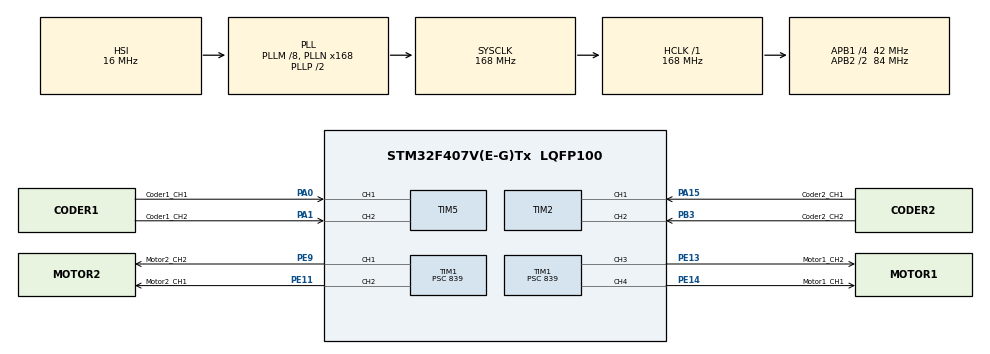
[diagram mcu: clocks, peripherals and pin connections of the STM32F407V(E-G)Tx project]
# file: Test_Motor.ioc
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Mcu.Family=STM32F4
Mcu.Name=STM32F407V(E-G)Tx
Mcu.Package=LQFP100
NVIC.PriorityGroup=NVIC_PRIORITYGROUP_4
NVIC.TIM6_DAC_IRQn=true\:0\:0\:false\:false\:true\:true\:true\:true
PA0-WKUP.GPIO_Label=Coder1_CH1
PA0-WKUP.Signal=S_TIM5_CH1
PA1.GPIO_Label=Coder1_CH2
PA1.Signal=S_TIM5_CH2
PA15.GPIO_Label=Coder2_CH1
PA15.Signal=S_TIM2_CH1_ETR
PB3.GPIO_Label=Coder2_CH2
PB3.Signal=S_TIM2_CH2
PC14-OSC32_IN.Mode=LSE-External-Oscillator
PC14-OSC32_IN.Signal=RCC_OSC32_IN
PC15-OSC32_OUT.Mode=LSE-External-Oscillator
PC15-OSC32_OUT.Signal=RCC_OSC32_OUT
PE11.GPIO_Label=Motor2_CH1
PE11.GPIO_Speed=GPIO_SPEED_FREQ_HIGH
PE11.Signal=S_TIM1_CH2
PE13.GPIO_Label=Motor1_CH2
PE13.GPIO_Speed=GPIO_SPEED_FREQ_HIGH
PE13.Signal=S_TIM1_CH3
PE14.GPIO_Label=Motor1_CH1
PE14.GPIO_Speed=GPIO_SPEED_FREQ_HIGH
PE14.Signal=S_TIM1_CH4
PE9.GPIO_Label=Motor2_CH2
PE9.GPIO_Speed=GPIO_SPEED_FREQ_HIGH
PE9.Signal=S_TIM1_CH1
PH0-OSC_IN.Mode=HSE-External-Oscillator
PH0-OSC_IN.Signal=RCC_OSC_IN
PH1-OSC_OUT.Mode=HSE-External-Oscillator
PH1-OSC_OUT.Signal=RCC_OSC_OUT
ProjectManager.HeapSize=0x200
ProjectManager.StackSize=0x400
ProjectManager.TargetToolchain=CMake
RCC.48MHZClocksFreq_Value=84000000
RCC.AHBFreq_Value=168000000
RCC.APB1CLKDivider=RCC_HCLK_DIV4
RCC.APB1Freq_Value=42000000
RCC.APB1TimFreq_Value=84000000
RCC.APB2CLKDivider=RCC_HCLK_DIV2
RCC.APB2Freq_Value=84000000
RCC.APB2TimFreq_Value=168000000
RCC.CortexFreq_Value=168000000
RCC.HCLKFreq_Value=168000000
RCC.HSE_VALUE=25000000
RCC.HSI_VALUE=16000000
RCC.PLLM=8
RCC.PLLN=168
RCC.SYSCLKFreq_VALUE=168000000
RCC.SYSCLKSource=RCC_SYSCLKSOURCE_PLLCLK
RCC.VCOOutputFreq_Value=336000000
SH.S_TIM1_CH1.0=TIM1_CH1,PWM Generation1 CH1
SH.S_TIM1_CH2.0=TIM1_CH2,PWM Generation2 CH2
SH.S_TIM1_CH3.0=TIM1_CH3,PWM Generation3 CH3
SH.S_TIM1_CH4.0=TIM1_CH4,PWM Generation4 CH4
SH.S_TIM2_CH1_ETR.0=TIM2_CH1,Encoder_Interface
SH.S_TIM2_CH2.0=TIM2_CH2,Encoder_Interface
SH.S_TIM5_CH1.0=TIM5_CH1,Encoder_Interface
SH.S_TIM5_CH2.0=TIM5_CH2,Encoder_Interface
TIM1.AutoReloadPreload=TIM_AUTORELOAD_PRELOAD_ENABLE
TIM1.Channel-PWM\ Generation1\ CH1=TIM_CHANNEL_1
TIM1.Channel-PWM\ Generation2\ CH2=TIM_CHANNEL_2
TIM1.Channel-PWM\ Generation3\ CH3=TIM_CHANNEL_3
TIM1.Channel-PWM\ Generation4\ CH4=TIM_CHANNEL_4
TIM1.Period=999
TIM1.Prescaler=839
TIM6.Period=10000
TIM6.Prescaler=83
VP_TIM1_VS_ClockSourceINT.Mode=Internal
VP_TIM6_VS_ClockSourceINT.Mode=Enable_Timer
board=custom

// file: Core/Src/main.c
/* USER CODE BEGIN Header */
/**
  ******************************************************************************
  * @file           : main.c
  * @brief          : Main program body
  ******************************************************************************
  * @attention
  *
  * Copyright (c) 2026 STMicroelectronics.
  * All rights reserved.
  *
  * This software is licensed under terms that can be found in the LICENSE file
  * in the root directory of this software component.
  * If no LICENSE file comes with this software, it is provided AS-IS.
  *
  ******************************************************************************
  */
/* USER CODE END Header */
#include "main.h"
#include "tim.h"
#include "gpio.h"

/* USER CODE BEGIN Includes */
#include "encoder_motor.h"
#include "motor_porting.h"
#include "pid.h"
#include <stdio.h>
/* USER CODE END Includes */

void SystemClock_Config(void);

int main(void)
{

  /* MCU Configuration--------------------------------------------------------*/

  /* Reset of all peripherals, Initializes the Flash interface and the Systick. */
  HAL_Init();

  /* Configure the system clock */
  SystemClock_Config();

  /* Initialize all configured peripherals */
  MX_GPIO_Init();
  MX_TIM1_Init();
  MX_TIM2_Init();
  MX_TIM5_Init();
  MX_TIM6_Init();
  /* USER CODE BEGIN 2 */
  motor_init();                      // 初始化电机
  encoder_motor_set_speed(&motor1, 2.0); // 设置目标转速
  encoder_motor_set_speed(&motor2, -2.0); // 设置目标转速
  /* USER CODE END 2 */

  /* Infinite loop */
  while (1)
  {

  }
}

void SystemClock_Config(void)
{
  RCC_OscInitTypeDef RCC_OscInitStruct = {0};
  RCC_ClkInitTypeDef RCC_ClkInitStruct = {0};

  /** Configure the main internal regulator output voltage
  */
  __HAL_RCC_PWR_CLK_ENABLE();
  __HAL_PWR_VOLTAGESCALING_CONFIG(PWR_REGULATOR_VOLTAGE_SCALE1);

  /** Initializes the RCC Oscillators according to the specified parameters
  * in the RCC_OscInitTypeDef structure.
  */
  RCC_OscInitStruct.OscillatorType = RCC_OSCILLATORTYPE_HSI;
  RCC_OscInitStruct.HSIState = RCC_HSI_ON;
  RCC_OscInitStruct.HSICalibrationValue = RCC_HSICALIBRATION_DEFAULT;
  RCC_OscInitStruct.PLL.PLLState = RCC_PLL_ON;
  RCC_OscInitStruct.PLL.PLLSource = RCC_PLLSOURCE_HSI;
  RCC_OscInitStruct.PLL.PLLM = 8;
  RCC_OscInitStruct.PLL.PLLN = 168;
  RCC_OscInitStruct.PLL.PLLP = RCC_PLLP_DIV2;
  RCC_OscInitStruct.PLL.PLLQ = 4;
  if (HAL_RCC_OscConfig(&RCC_OscInitStruct) != HAL_OK)
  {
    Error_Handler();
  }

  /** Initializes the CPU, AHB and APB buses clocks
  */
  RCC_ClkInitStruct.ClockType = RCC_CLOCKTYPE_HCLK|RCC_CLOCKTYPE_SYSCLK
                              |RCC_CLOCKTYPE_PCLK1|RCC_CLOCKTYPE_PCLK2;
  RCC_ClkInitStruct.SYSCLKSource = RCC_SYSCLKSOURCE_PLLCLK;
  RCC_ClkInitStruct.AHBCLKDivider = RCC_SYSCLK_DIV1;
  RCC_ClkInitStruct.APB1CLKDivider = RCC_HCLK_DIV4;
  RCC_ClkInitStruct.APB2CLKDivider = RCC_HCLK_DIV2;

  if (HAL_RCC_ClockConfig(&RCC_ClkInitStruct, FLASH_LATENCY_5) != HAL_OK)
  {
    Error_Handler();
  }
}

void Error_Handler(void)
{
  __disable_irq();
  while (1)
  {
  }
}
